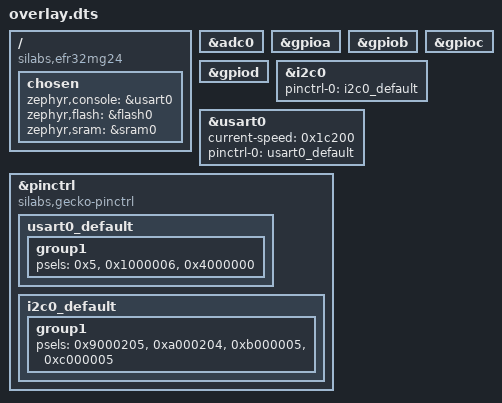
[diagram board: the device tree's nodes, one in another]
/ {
	compatible = "silabs,efr32mg24", "silabs,efr32mg24_brd2601b";
	chosen {
		zephyr,console = &usart0;
		zephyr,flash = &flash0;
		zephyr,sram = &sram0;
	};
};
&adc0{
	status = "okay";
};
&gpioa{
	status = "okay";
};
&gpiob{
	status = "okay";
};
&gpioc{
	status = "okay";
};
&gpiod{
	status = "okay";
};
&i2c0{
	status = "okay";
	pinctrl-0 = < &i2c0_default >;
	pinctrl-names = "default";
};
&usart0{
	status = "okay";
	current-speed = < 0x1c200 >;
	pinctrl-0 = < &usart0_default >;
	pinctrl-names = "default";
};
&pinctrl{
	compatible = "silabs,gecko-pinctrl";
	usart0_default: usart0_default {
		group1 {
			psels = < 0x5 >, < 0x1000006 >, < 0x4000000 >;
		};
	};
	i2c0_default: i2c0_default {
		group1 {
			psels = < 0x9000205 >, < 0xa000204 >, < 0xb000005 >, < 0xc000005 >;
		};
	};
};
